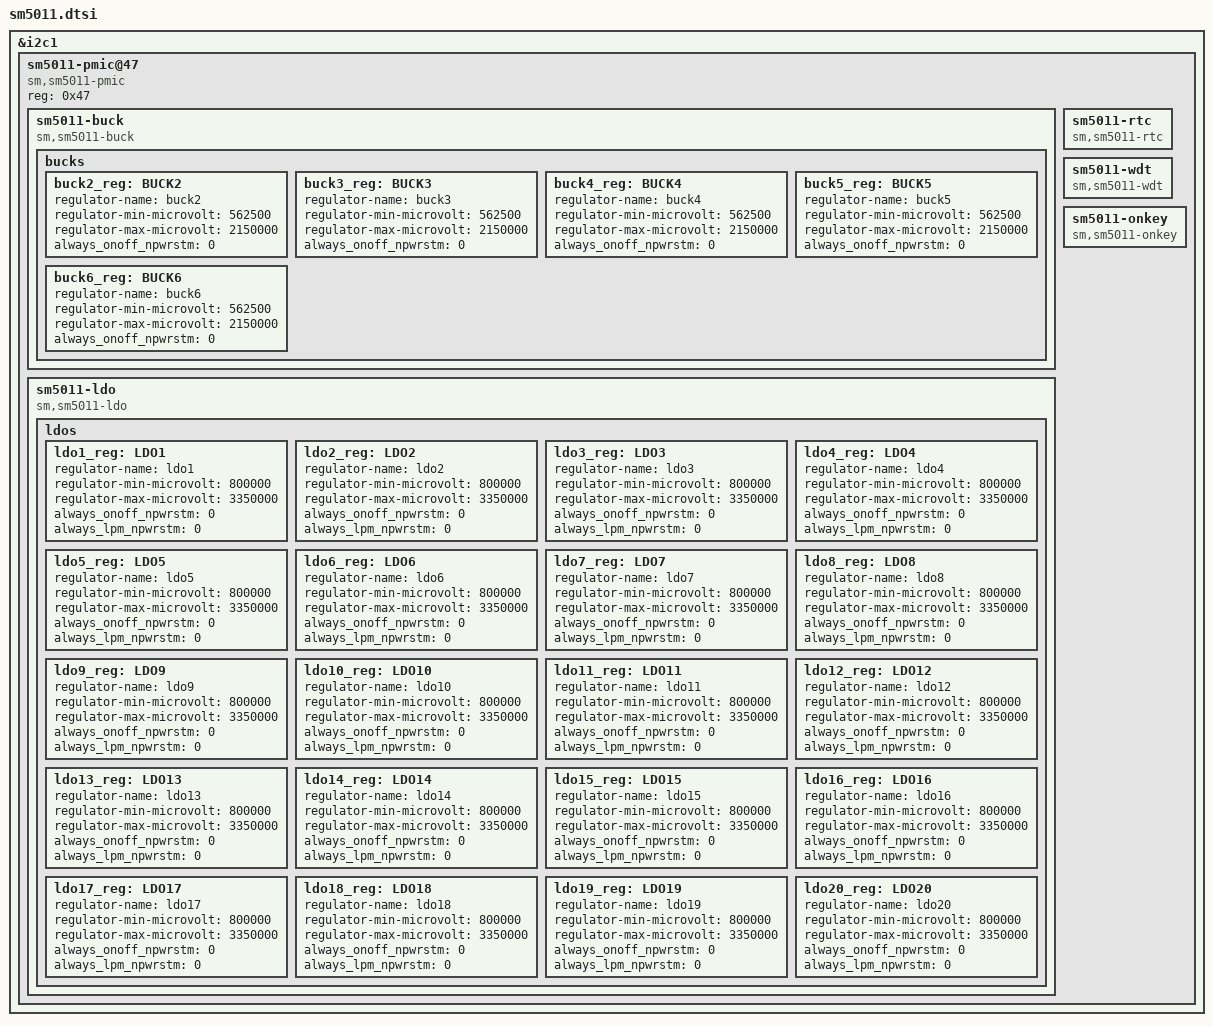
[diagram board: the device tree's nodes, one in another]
// Definitions for sm5011 from Siliconmitus

&i2c1 {
	#address-cells = <1>;
	#size-cells = <0>;
	status = "okay";

	sm5011-pmic@47 {
		compatible = "sm,sm5011-pmic";
		reg = <0x47>;				
		status = "okay";

		sm5011-buck {
			compatible = "sm,sm5011-buck";
			status = "okay";
			bucks {						
				buck2_reg: BUCK2 {
					regulator-name = "buck2";
					regulator-min-microvolt = <562500>;
					regulator-max-microvolt = <2150000>;
					always_onoff_npwrstm = <0>;	/* 0 : On/Off regardless of nPWRSTM Pin, 1 : On/Off by nPWRSTM Pin */
				};
				buck3_reg: BUCK3 {
					regulator-name = "buck3";
					regulator-min-microvolt = <562500>;
					regulator-max-microvolt = <2150000>;
					always_onoff_npwrstm = <0>;	/* 0 : On/Off regardless of nPWRSTM Pin, 1 : On/Off by nPWRSTM Pin */					
				};
				buck4_reg: BUCK4 {
					regulator-name = "buck4";
					regulator-min-microvolt = <562500>;
					regulator-max-microvolt = <2150000>;
					always_onoff_npwrstm = <0>;	/* 0 : On/Off regardless of nPWRSTM Pin, 1 : On/Off by nPWRSTM Pin */					
				};
				buck5_reg: BUCK5 {
					regulator-name = "buck5";
					regulator-min-microvolt = <562500>;
					regulator-max-microvolt = <2150000>;
					always_onoff_npwrstm = <0>;	/* 0 : On/Off regardless of nPWRSTM Pin, 1 : On/Off by nPWRSTM Pin */					
				};
				buck6_reg: BUCK6 {
					regulator-name = "buck6";
					regulator-min-microvolt = <562500>;
					regulator-max-microvolt = <2150000>;
					always_onoff_npwrstm = <0>;	/* 0 : On/Off regardless of nPWRSTM Pin, 1 : On/Off by nPWRSTM Pin */					
				};
			};					
		};
		sm5011-ldo {
			compatible = "sm,sm5011-ldo";
			status = "okay";
			ldos {									
				ldo1_reg: LDO1 {
					regulator-name = "ldo1";
					regulator-min-microvolt = <800000>;
					regulator-max-microvolt = <3350000>;
					always_onoff_npwrstm = <0>;	/* 0 : On/Off regardless of nPWRSTM Pin, 1 : On/Off by nPWRSTM Pin */
					always_lpm_npwrstm = <0>; /* 0 : LPM Enable/Disable regardless of nPWRSTM Pin, 1 : LPM Enable/Disable by nPWRSTM Pin */
				};
				ldo2_reg: LDO2 {
					regulator-name = "ldo2";
					regulator-min-microvolt = <800000>;
					regulator-max-microvolt = <3350000>;
					always_onoff_npwrstm = <0>;	/* 0 : On/Off regardless of nPWRSTM Pin, 1 : On/Off by nPWRSTM Pin */
					always_lpm_npwrstm = <0>; /* 0 : LPM Enable/Disable regardless of nPWRSTM Pin, 1 : LPM Enable/Disable by nPWRSTM Pin */					
				};
				ldo3_reg: LDO3 {
					regulator-name = "ldo3";
					regulator-min-microvolt = <800000>;
					regulator-max-microvolt = <3350000>;
					always_onoff_npwrstm = <0>;	/* 0 : On/Off regardless of nPWRSTM Pin, 1 : On/Off by nPWRSTM Pin */
					always_lpm_npwrstm = <0>; /* 0 : LPM Enable/Disable regardless of nPWRSTM Pin, 1 : LPM Enable/Disable by nPWRSTM Pin */					
				};
				ldo4_reg: LDO4 {
					regulator-name = "ldo4";
					regulator-min-microvolt = <800000>;
					regulator-max-microvolt = <3350000>;
					always_onoff_npwrstm = <0>;	/* 0 : On/Off regardless of nPWRSTM Pin, 1 : On/Off by nPWRSTM Pin */
					always_lpm_npwrstm = <0>; /* 0 : LPM Enable/Disable regardless of nPWRSTM Pin, 1 : LPM Enable/Disable by nPWRSTM Pin */					
				};
				ldo5_reg: LDO5 {
					regulator-name = "ldo5";
					regulator-min-microvolt = <800000>;
					regulator-max-microvolt = <3350000>;
					always_onoff_npwrstm = <0>;	/* 0 : On/Off regardless of nPWRSTM Pin, 1 : On/Off by nPWRSTM Pin */
					always_lpm_npwrstm = <0>; /* 0 : LPM Enable/Disable regardless of nPWRSTM Pin, 1 : LPM Enable/Disable by nPWRSTM Pin */
				};
				ldo6_reg: LDO6 {
					regulator-name = "ldo6";
					regulator-min-microvolt = <800000>;
					regulator-max-microvolt = <3350000>;
					always_onoff_npwrstm = <0>;	/* 0 : On/Off regardless of nPWRSTM Pin, 1 : On/Off by nPWRSTM Pin */
					always_lpm_npwrstm = <0>; /* 0 : LPM Enable/Disable regardless of nPWRSTM Pin, 1 : LPM Enable/Disable by nPWRSTM Pin */					
				};
				ldo7_reg: LDO7 {
					regulator-name = "ldo7";
					regulator-min-microvolt = <800000>;
					regulator-max-microvolt = <3350000>;
					always_onoff_npwrstm = <0>;	/* 0 : On/Off regardless of nPWRSTM Pin, 1 : On/Off by nPWRSTM Pin */
					always_lpm_npwrstm = <0>; /* 0 : LPM Enable/Disable regardless of nPWRSTM Pin, 1 : LPM Enable/Disable by nPWRSTM Pin */					
				};
				ldo8_reg: LDO8 {
					regulator-name = "ldo8";
					regulator-min-microvolt = <800000>;
					regulator-max-microvolt = <3350000>;
					always_onoff_npwrstm = <0>;	/* 0 : On/Off regardless of nPWRSTM Pin, 1 : On/Off by nPWRSTM Pin */
					always_lpm_npwrstm = <0>; /* 0 : LPM Enable/Disable regardless of nPWRSTM Pin, 1 : LPM Enable/Disable by nPWRSTM Pin */					
				};
				ldo9_reg: LDO9 {
					regulator-name = "ldo9";
					regulator-min-microvolt = <800000>;
					regulator-max-microvolt = <3350000>;
					always_onoff_npwrstm = <0>;	/* 0 : On/Off regardless of nPWRSTM Pin, 1 : On/Off by nPWRSTM Pin */
					always_lpm_npwrstm = <0>; /* 0 : LPM Enable/Disable regardless of nPWRSTM Pin, 1 : LPM Enable/Disable by nPWRSTM Pin */					
				};
				ldo10_reg: LDO10 {
					regulator-name = "ldo10";
					regulator-min-microvolt = <800000>;
					regulator-max-microvolt = <3350000>;
					always_onoff_npwrstm = <0>;	/* 0 : On/Off regardless of nPWRSTM Pin, 1 : On/Off by nPWRSTM Pin */
					always_lpm_npwrstm = <0>; /* 0 : LPM Enable/Disable regardless of nPWRSTM Pin, 1 : LPM Enable/Disable by nPWRSTM Pin */					
				};
				ldo11_reg: LDO11 {
					regulator-name = "ldo11";
					regulator-min-microvolt = <800000>;
					regulator-max-microvolt = <3350000>;
					always_onoff_npwrstm = <0>;	/* 0 : On/Off regardless of nPWRSTM Pin, 1 : On/Off by nPWRSTM Pin */
					always_lpm_npwrstm = <0>; /* 0 : LPM Enable/Disable regardless of nPWRSTM Pin, 1 : LPM Enable/Disable by nPWRSTM Pin */					
				};
				ldo12_reg: LDO12 {
					regulator-name = "ldo12";
					regulator-min-microvolt = <800000>;
					regulator-max-microvolt = <3350000>;
					always_onoff_npwrstm = <0>;	/* 0 : On/Off regardless of nPWRSTM Pin, 1 : On/Off by nPWRSTM Pin */
					always_lpm_npwrstm = <0>; /* 0 : LPM Enable/Disable regardless of nPWRSTM Pin, 1 : LPM Enable/Disable by nPWRSTM Pin */					
				};
				ldo13_reg: LDO13 {
					regulator-name = "ldo13";
					regulator-min-microvolt = <800000>;
					regulator-max-microvolt = <3350000>;
					always_onoff_npwrstm = <0>;	/* 0 : On/Off regardless of nPWRSTM Pin, 1 : On/Off by nPWRSTM Pin */
					always_lpm_npwrstm = <0>; /* 0 : LPM Enable/Disable regardless of nPWRSTM Pin, 1 : LPM Enable/Disable by nPWRSTM Pin */					
				};
				ldo14_reg: LDO14 {
					regulator-name = "ldo14";
					regulator-min-microvolt = <800000>;
					regulator-max-microvolt = <3350000>;
					always_onoff_npwrstm = <0>;	/* 0 : On/Off regardless of nPWRSTM Pin, 1 : On/Off by nPWRSTM Pin */
					always_lpm_npwrstm = <0>; /* 0 : LPM Enable/Disable regardless of nPWRSTM Pin, 1 : LPM Enable/Disable by nPWRSTM Pin */					
				};
				ldo15_reg: LDO15 {
					regulator-name = "ldo15";
					regulator-min-microvolt = <800000>;
					regulator-max-microvolt = <3350000>;
					always_onoff_npwrstm = <0>;	/* 0 : On/Off regardless of nPWRSTM Pin, 1 : On/Off by nPWRSTM Pin */
					always_lpm_npwrstm = <0>; /* 0 : LPM Enable/Disable regardless of nPWRSTM Pin, 1 : LPM Enable/Disable by nPWRSTM Pin */					
				};
				ldo16_reg: LDO16 {
					regulator-name = "ldo16";
					regulator-min-microvolt = <800000>;
					regulator-max-microvolt = <3350000>;
					always_onoff_npwrstm = <0>;	/* 0 : On/Off regardless of nPWRSTM Pin, 1 : On/Off by nPWRSTM Pin */
					always_lpm_npwrstm = <0>; /* 0 : LPM Enable/Disable regardless of nPWRSTM Pin, 1 : LPM Enable/Disable by nPWRSTM Pin */					
				};
				ldo17_reg: LDO17 {
					regulator-name = "ldo17";
					regulator-min-microvolt = <800000>;
					regulator-max-microvolt = <3350000>;
					always_onoff_npwrstm = <0>;	/* 0 : On/Off regardless of nPWRSTM Pin, 1 : On/Off by nPWRSTM Pin */
					always_lpm_npwrstm = <0>; /* 0 : LPM Enable/Disable regardless of nPWRSTM Pin, 1 : LPM Enable/Disable by nPWRSTM Pin */					
				};
				ldo18_reg: LDO18 {
					regulator-name = "ldo18";
					regulator-min-microvolt = <800000>;
					regulator-max-microvolt = <3350000>;
					always_onoff_npwrstm = <0>;	/* 0 : On/Off regardless of nPWRSTM Pin, 1 : On/Off by nPWRSTM Pin */
					always_lpm_npwrstm = <0>; /* 0 : LPM Enable/Disable regardless of nPWRSTM Pin, 1 : LPM Enable/Disable by nPWRSTM Pin */					
				};
				ldo19_reg: LDO19 {
					regulator-name = "ldo19";
					regulator-min-microvolt = <800000>;
					regulator-max-microvolt = <3350000>;
					always_onoff_npwrstm = <0>;	/* 0 : On/Off regardless of nPWRSTM Pin, 1 : On/Off by nPWRSTM Pin */
					always_lpm_npwrstm = <0>; /* 0 : LPM Enable/Disable regardless of nPWRSTM Pin, 1 : LPM Enable/Disable by nPWRSTM Pin */					
				};	
				ldo20_reg: LDO20 {
					regulator-name = "ldo20";
					regulator-min-microvolt = <800000>;
					regulator-max-microvolt = <3350000>;
					always_onoff_npwrstm = <0>;	/* 0 : On/Off regardless of nPWRSTM Pin, 1 : On/Off by nPWRSTM Pin */
					always_lpm_npwrstm = <0>; /* 0 : LPM Enable/Disable regardless of nPWRSTM Pin, 1 : LPM Enable/Disable by nPWRSTM Pin */					
				};					
			};					
		};
		sm5011-rtc {
			compatible = "sm,sm5011-rtc";
			status = "okay";
		};

		sm5011-wdt {
			compatible = "sm,sm5011-wdt";
			status = "okay";
		};		
		sm5011-onkey {
			compatible = "sm,sm5011-onkey";
			status = "okay";
		};
	};
};
